# sdmmc_secure register map
Vendor: Texas Instruments
Peripheral module from a debugger description file (folder CC35X1E).
Registers are 32-bit, access per field, reset 0x0 unless marked. A register's access mark holds for its fields unless they carry their own. Offsets are as the file gives them; lines under a group give offsets from that group; [hi:lo] are bit positions; {n}, {i} and the like mark numbered series; 'fields as' and 'values as' point back to an identical list; <NAME> marks a mode.

## sdmmc_secure (part 1 of 2)
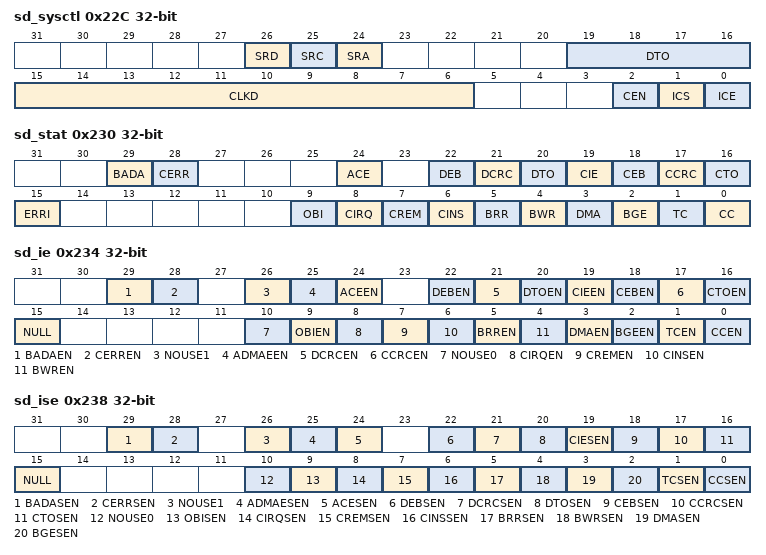
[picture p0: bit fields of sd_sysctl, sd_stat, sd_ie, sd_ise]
0x22C sd_sysctl — SD System Control Register This register defines the system controls clock frequency management and data timeout. SD_SYSCTL[23:16] = Timeout control SD_SYSCTL[15:0] = Clock control
  [26] SRD rw — Software reset for mmc_dat line This bit is set to 1 for reset and released to 0 when completed. Note: This subreset should not to be used by software, as it can lead to unexpected side-effects. Reset of the SDMMC module should always be through GPRCM.RSTCTL.RESETASSERT
    0=COMPL (Reset completed); 1=ASSERT (Reset asserted)
  [25] SRC rw — Software reset for mmc_cmd line This bit is set to 1 for reset and released to 0 when completed. Note: This subreset should not to be used by software, as it can lead to unexpected side-effects. Reset of the SDMMC module should always be through GPRCM.RSTCTL.RESETASSERT
    0=COMPL (Reset completed); 1=ASSERT (Reset asserted)
  [24] SRA rw — Software reset for all This bit is set to 1 for reset, and released to 0 when completed. Note: This subreset should not to be used by software, as it can lead to unexpected side-effects. Reset of the SDMMC module should always be through GPRCM.RSTCTL.RESETASSERT
    0=COMPL (Reset completed); 1=ASSERT (Reset asserted)
  [19:16] DTO rw — Data timeout counter value and busy timeout This value determines the interval to detect mmc_dat lines timeouts. The host driver needs to set this bitfield based on: - the maximum read access time (NAC) (Refer to the SD Specification Part1 Physical Layer) - the data read access time values (TAAC and NSAC) in the card specific data register (CSD) of the card - the timeout clock base frequency (SD_CAPA.TCF) If the card does not respond within the specified number of cycles, a data timeout error occurs (SD_STAT.DTO). The Data timeout counter can also be used to check busy duration, to generate busy timeout for commands with busy response or for busy programming during a write command. Timeout on CRC status is generated if no CRC token is present after a block write. 0h = TCF x 2^13 1h = TCF x 2^14 Eh = TCF x 2^27 Fh = Reserved
    0=MINIMUM (Minimum value); 14=MAXIMUM (Maximum value)
  [15:6] CLKD rw — Clock frequency select This bitfield defines the ratio between a reference clock frequency (system dependent) and the output clock frequency on the mmc_clk pin of the memory card (MMC, SD, or SDIO). 0h = Clock Ref bypass 1h = Clock Ref bypass 2h = Clock Ref / 2 3h = Clock Ref / 3 3FFh = Clock Ref / 1023
    0=MINIMUM (Minimum value); 0x3FF=MAXIMUM (Maximum value)
  [2] CEN rw — Card clock enable This bit controls the clock to the card.
    0=OFF (The clock is not provided to the card . Clock frequency can be changed.); 1=ON (The clock is provided to the card and can be automatically gated when SD_SYSCONFIG.AUTOIDLE bit is set to 1 (default value). The host driver must wait to set this bit to 1 until the internal clock is stable (SYSSTAT.ICS).)
  [1] ICS ro — Internal clock stable (status) This bit indicates that the internal clock is stable
    0=NOSTAB (The internal clock is not stable); 1=STAB (The internal clock is stable after enabling the clock (SD_SYSCTL.ICEN) or after changing the clock ratio (SD_SYSCTL.CLKD).)
  [0] ICE rw — Internal clock enable This bit controls the internal clock activity. In very low power state, the internal clock is stopped. Note: The activity of the debounce clock (used for wake-up events) and the interface clock (used for reads and writes to the module register map) are not affected by this register.
    0=STOP (The internal clock is stopped (very low power state).); 1=RUN (The internal clock oscillates and can be automatically gated when SD_SYSCONFIG.AUTOIDLE bit is set to 1 (default value).)
0x230 sd_stat — The interrupt status regroups all the status of the module internal events that can generate an interrupt. SD_STAT[31:16] = Error Interrupt Status SD_STAT[15:0] = Normal Interrupt Status The error bits are located in the upper 16 bits of the SD_STAT register. All bits are cleared by writing a 1 to them. Additionally, bits 15 and 8 serve as special error bits. These cannot be cleared by writing a 1 to them. Bit 15 (ERRI) is automatically cleared when the error causing to ERRI to be set is handled. (that is, when bits 31:16 are cleared, bit 15 will be automatically cleared). Bit 8 (CIRQ) is cleared by writing a 0 to SD_IE[8] (masking the interrupt) and servicing the interrupt.
  [all] fields
    0=NOINT (No interrupt occured); 1=INT (Interrupt occured)
  [29] BADA rw — Bad access to data space. This bit is set automatically to indicate a bad access to buffer when not allowed: During a read access to the data register (SD_DATA) while buffer reads are not allowed (SD_PSTATE[11] BRE bit =0). During a write access to the data register (SD_DATA) while buffer writes are not allowed (SD_PSTATE[10] BWE bit=0). 0h (W) = Status bit unchanged 0h (R) = No interrupt 1h (W) = Status is cleared. 1h (R) = Bad access
  [28] CERR rw — Card error. This bit is set automatically when there is at least one error in a response of type R1, R1b, R6, R5 or R5b. Only bits referenced as type E (error) in status field in the response can set a card status error. An error bit in the response is flagged only if corresponding bit in card status response error SD_CSRE in set. There is no card error detection for autoCMD12 command. The host driver shall read SD_RSP76 register to detect error bits in the command response. 0h (W) = Status bit unchanged 0h (R) = No error 1h (W) = Status is cleared. 1h (R) = Card error
  [24] ACE rw — Auto CMD12 error. This bit is set automatically when one of the bits in Auto CMD12 Error status register has changed from 0 to 1. 0h (W) = Status bit unchanged 0h (R) = No error 1h (W) = Status is cleared. 1h (R) = AutoCMD12 error
  [22] DEB rw — Data End Bit error. This bit is set automatically when detecting a 0 at the end bit position of read data on mmc_dat line or at the end position of the CRC status in write mode. 0h (W) = Status bit unchanged 0h (R) = No error 1h (W) = Status is cleared. 1h (R) = Data end bit error
  [21] DCRC rw — Data CRC Error. This bit is set automatically when there is a CRC16 error in the data phase response following a block read command or if there is a 3-bit CRC status different of a position "010" token during a block write command. 0h (W) = Status bit unchanged 0h (R) = No error 1h (W) = Status is cleared. 1h (R) = Data CRC error
  [20] DTO rw — Data timeout error. This bit is set automatically according to the following conditions: Busy timeout for R1b, R5b response type. Busy timeout after write CRC status. Write CRC status timeout. Read data timeout. 0h (W) = Status bit unchanged 0h (R) = No error 1h (W) = Status is cleared. 1h (R) = Time out
  [19] CIE rw — Command index error. This bit is set automatically when response index differs from corresponding command index previously emitted. It depends on the enable bit (SD_CMD[20] CICE). 0h (W) = Status bit unchanged 0h (R) = No error 1h (W) = Status is cleared. 1h (R) = Command index error
  [18] CEB rw — Command end bit error. This bit is set automatically when detecting a 0 at the end bit position of a command response. 0h (W) = Status bit unchanged 0h (R) = No error 1h (W) = Status is cleared. 1h (R) = Command end bit error
  [17] CCRC rw — Command CRC error. This bit is set automatically when there is a CRC7 error in the command response depending on the enable bit (SD_CMD[19] CCCE). 0h (W) = Status bit unchanged 0h (R) = No error 1h (W) = Status is cleared. 1h (R) = Command CRC error
  [16] CTO rw — Command timeout error. This bit is set automatically when no response is received within 64 clock cycles from the end bit of the command. For commands that reply within 5 clock cycles - the timeout is still detected at 64 clock cycles. 0h (W) = Status bit unchanged 0h (R) = No error 1h (W) = Status is cleared. 1h (R) = Time Out
  [15] ERRI ro — Error interrupt. If any of the bits in the Error Interrupt Status register (SD_STAT [31:16]) are set, then this bit is set to 1. Therefore the host driver can efficiently test for an error by checking this bit first. Writes to this bit are ignored. 0h (R) = No interrupt 1h (R) = Error interrupt event(s) occurred
  [9] OBI rw — Out-of-band interrupt (This interrupt is only useful for MMC card). Note: Out-of-band interrupt (OBI) is not supported.
  [8] CIRQ ro — Card interrupt. This bit is only used for SD and SDIO cards. In 1-bit mode, interrupt source is asynchronous (can be a source of asynchronous wake-up). In 4-bit mode, interrupt source is sampled during the interrupt cycle. In CE-ATA mode, interrupt source is detected when the card drives mmc_cmd line to zero during one cycle after data transmission end. All modes above are fully exclusive. The controller interrupt must be clear by setting SD_IE[8] CIRQ_ENABLE to 0, then the host driver must start the interrupt service with card (clearing card interrupt status) to remove card interrupt source. Otherwise the Controller interrupt will be reasserted as soon as SD_IE[8] CIRQ_ENABLE is set to 1. Writes to this bit are ignored. 0h (R) = No card interrupt 1h (R) = Generate card interrupt
  [7] CREM rw — Card Removal. This bit is set automatically when SD_PSTATE[CINS] changes from 1 to 0. A clear of this bit doesn't affect Card inserted present state (SD_PSTATE[CINS]). 0h (W) = Status bit unchanged 0h (R) = Card State stable or debouncing 1h (W) = Status is cleared 1h (R) = Card Removed
  [6] CINS rw — Card Insertion. This bit is set automatically when SD_PSTATE[CINS] changes from 0 to 1. A clear of this bit doesn't affect Card inserted present state (SD_PSTATE[CINS]). 0h (W) = Status bit unchanged 0h (R) = Card State stable or debouncing 1h (W) = Status is cleared. 1h (R) = Card inserted
  [5] BRR rw — Buffer read ready. This bit is set automatically during a read operation to the card (see class 2 - block oriented read commands) when one block specified by the SD_BLK [10:0] BLEN bit field is completely written in the buffer. It indicates that the memory card has filled out the buffer and that the local host needs to empty the buffer by reading it. Note: If the DMA receive-mode is enabled, this bit is never set instead a DMA receive request to the main DMA controller of the system is generated. 0h (W) = Status bit unchanged 0h (R) = Not ready to read buffer 1h (W) = Status is cleared. 1h (R) = Ready to read buffer
  [4] BWR rw — Buffer write ready. This bit is set automatically during a write operation to the card (see class 4 - block oriented write command) when the host can write a complete block as specified by SD_BLK [10:0] BLEN. It indicates that the memory card has emptied one block from the buffer and that the local host is able to write one block of data into the buffer. Note: If the DMA transmit mode is enabled, this bit is never set instead, a DMA transmit request to the main DMA controller of the system is generated. 0h (W) = Status bit unchanged 0h (R) = Not ready to write buffer 1h (W) = Status is cleared. 1h (R) = Ready to write buffer
  [3] DMA rw — DMA Interrupt This status is set when an interrupt is required after the data transfer is complete.
  [2] BGE rw — Block gap event. When a stop at block gap is requested (SD_HCTL[16] SBGR bit), this bit is automatically set when transaction is stopped at the block gap during a read or write operation. 0h (W) = Status bit unchanged 0h (R) = No block gap event 1h (W) = Status is cleared 1h (R) = Transaction stopped at block gap
  [1] TC rw — Transfer completed. This bit is always set when a read/write transfer is completed or between two blocks when the transfer is stopped due to a stop at block gap request (SD_HCTL[16] SBGR bit). 0h (W) = Status bit unchanged 0h (R) = No transfer complete 1h (W) = Status is cleared 1h (R) = Data transfer complete
  [0] CC rw — Command complete. This bit is set when a 1-to-0 transition occurs in the register command inhibit (SD_PSTATE[0] CMDI bit) 0h (W) = Status bit unchanged 0h (R) = No command complete 1h (W) = Status is cleared 1h (R) = Command complete
0x234 sd_ie — This register allows to enable/disable the module to set status bits on an event-by-event basis. SD_IE[31:16] = Error Interrupt Status Enable SD_IE[15:0] = Normal Interrupt Status Enable
  [29] BADAEN rw — Bad access to data space interrupt enable
    1=ENABLE (Interrupt enabled); 0=MSK (Interrupt masked)
  [28] CERREN rw — Card error interrupt enable
    1=ENABLE (Interrupt enabled); 0=MSK (Interrupt masked)
  [26] NOUSE1 rw — No use Note: Writing values other than 0 might produce undesired results. Always set this bits to 0.
    0=MIN (Minimum value); 1=MAX (Maximum value)
  [25] ADMAEEN rw — ADMA Error Status Enable Note: This functionality is not supported, since MADMA_EN is set to 0 in the design.
    1=ENABLE (Interrupt enabled); 0=MSK (Interrupt masked)
  [24] ACEEN rw — Auto CMD12 error interrupt enable
    1=ENABLE (Interrupt enabled); 0=MSK (Interrupt masked)
  [22] DEBEN rw — Data end bit error interrupt enable
    1=ENABLE (Interrupt enabled); 0=MSK (Interrupt masked)
  [21] DCRCEN rw — Data CRC error interrupt enable
    1=ENABLE (Interrupt enabled); 0=MSK (Interrupt masked)
  [20] DTOEN rw — Data timeout error interrupt enable
    1=ENABLE (Interrupt enabled); 0=MSK (Interrupt masked)
  [19] CIEEN rw — Command index error interrupt enable
    1=ENABLE (Interrupt enabled); 0=MSK (Interrupt masked)
  [18] CEBEN rw — Command end bit error interrupt enable
    1=ENABLE (Interrupt enabled); 0=MSK (Interrupt masked)
  [17] CCRCEN rw — Command CRC error interrupt enable
    1=ENABLE (Interrupt enabled); 0=MSK (Interrupt masked)
  [16] CTOEN rw — Command timeout error interrupt enable
    1=ENABLE (Interrupt enabled); 0=MSK (Interrupt masked)
  [15] NULL ro — Fixed to 0. The host driver shall control error interrupts using the Error Interrupt Signal Enable register. Writes to this bit are ignored.
    1=ENABLE (Interrupt enabled); 0=MSK (Interrupt masked)
  [10] NOUSE0 rw — No use Note: Writing values other than 0 might produce undesired results. Always set this bits to 0.
    0=MIN (Minimum value); 1=MAX (Maximum value)
  [9] OBIEN rw — Out-of-band interrupt enable A write to this register when SD_CON[14] OBIE is cleared to 0 is ignored. Note: The OBI functionallity is not supported!
    1=ENABLE (Interrupt enabled); 0=MSK (Interrupt masked)
  [8] CIRQEN rw — Card interrupt enable. A clear of this bit also clears the corresponding status bit. During 1-bit mode, if the interrupt routine does not remove the source of a card interrupt in the SDIO card, the status bit is reasserted when this bit is set to 1.
    1=ENABLE (Interrupt enabled); 0=MSK (Interrupt masked)
  [7] CREMEN rw — Card Removal interrupt Enable
    1=ENABLE (Interrupt enabled); 0=MSK (Interrupt masked)
  [6] CINSEN rw — Card Insertion interrupt Enable
    1=ENABLE (Interrupt enabled); 0=MSK (Interrupt masked)
  [5] BRREN rw — Buffer read ready interrupt enable
    1=ENABLE (Interrupt enabled); 0=MSK (Interrupt masked)
  [4] BWREN rw — Buffer write ready interrupt enable
    1=ENABLE (Interrupt enabled); 0=MSK (Interrupt masked)
  [3] DMAEN rw — DMA interrupt enable
    1=ENABLE (Interrupt enabled); 0=MSK (Interrupt masked)
  [2] BGEEN rw — Block gap event interrupt enable
    1=ENABLE (Interrupt enabled); 0=MSK (Interrupt masked)
  [1] TCEN rw — Transfer completed interrupt enable
    1=ENABLE (Interrupt enabled); 0=MSK (Interrupt masked)
  [0] CCEN rw — Command completed interrupt enable
    0=MSK (Interrupt masked); 1=ENABLE (Interrupt enabled)
0x238 sd_ise — This register allows to enable/disable the module internal interrupt signaling on an event-by-event basis. SD_ISE[31:16] = Error Interrupt Signal Enable SD_ISE[15:0] = Normal Interrupt Signal Enable
  [29] BADASEN rw — Bad access to data space interrupt enable
    0=DISABLE (Status Interrupt signaling disabled); 1=ENABLE (Status Interrupt signaling enabled)
  [28] CERRSEN rw — Card error interrupt signal status enable
    values as BADASEN
  [26] NOUSE1 rw — No use Note: Writing values other than 0 might produce undesired results. Always set this bit to 0.
    0=LOW (Always set this bit to 0); 1=HIGH (Do not set this bit)
  [25] ADMAESEN rw — ADMA Error Signal Enable Note: This functionality is not supported, since MADMA_EN is set to 0 in the design.
    values as BADASEN
  [24] ACESEN rw — Auto CMD12 error signal status enable
    values as BADASEN
  [22] DEBSEN rw — Data end bit error signal status enable
    values as BADASEN
  [21] DCRCSEN rw — Data CRC error signal status enable
    values as BADASEN
  [20] DTOSEN rw — Data timeout error signal status enable
    values as BADASEN
  [19] CIESEN rw — Command index error signal status enable
    values as BADASEN
  [18] CEBSEN rw — Command end bit error signal status enable
    values as BADASEN
  [17] CCRCSEN rw — Command CRC error signal status enable
    values as BADASEN
  [16] CTOSEN rw — Command timeout error signal status enable
    1=ENABLE (Status Interrupt signaling enabled); 0=DISABLE (Status Interrupt signaling disabled)
  [15] NULL ro — Fixed to 0. The host driver shall control error interrupts using the Error Interrupt Signal Enable register. Writes to this bit are ignored.
    1=ENABLE (Interrupt enabled); 0=MSK (Interrupt masked)
  [10] NOUSE0 rw — No use Note: Writing values other than 0 might produce undesired results. Always set this bit to 0.
    values as NOUSE1
  [9] OBISEN rw — Out-of-band interrupt signal status enable. A write to this register when SD_CON[14] OBIE is cleared to 0 is ignored. Note: The OBI functionallity is not supported!
    values as BADASEN
  [8] CIRQSEN rw — Card interrupt signal status enable. A clear of this bit also clears the corresponding status bit. During 1-bit mode, if the interrupt routine does not remove the source of a card interrupt in the SDIO card, the status bit is reasserted when this bit is set to 1.
    values as CTOSEN
  [7] CREMSEN rw — Card Removal signal status enable
    values as BADASEN
  [6] CINSSEN rw — Card Insertion signal status enable.
    values as BADASEN
  [5] BRRSEN rw — Buffer read ready signal status enable
    values as BADASEN
  [4] BWRSEN rw — Buffer write ready signal status enable
    values as BADASEN
  [3] DMASEN rw — DMA signal status enable
    values as BADASEN
  [2] BGESEN rw — Block gap event signal status enable
    values as BADASEN
  [1] TCSEN rw — Transfer completed signal status enable
    values as BADASEN
  [0] CCSEN rw — Command completed signal status enable
    values as BADASEN
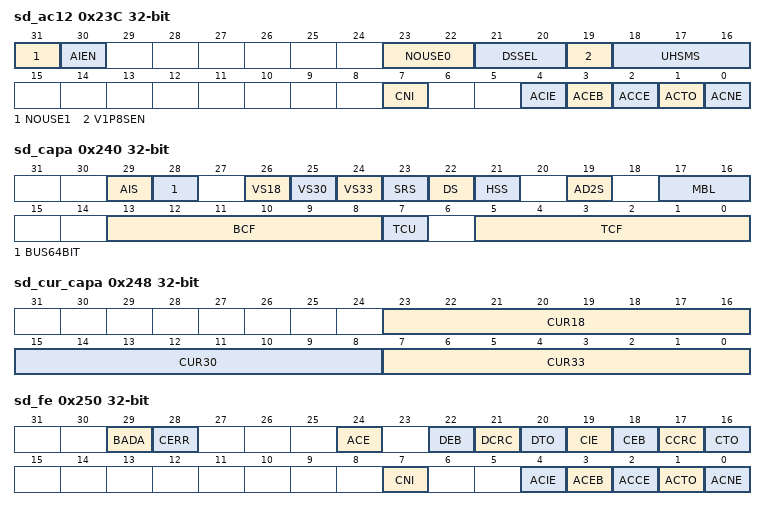
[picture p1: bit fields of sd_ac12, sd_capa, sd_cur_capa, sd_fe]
0x23C sd_ac12 — SD_AC12 Error register The host driver may determine which of the errors cases related to Auto CMD12 has occurred by checking this SD_AC12 register when an auto CMD12 error interrupt occurs. This register is valid only when auto CMD12 is enabled (SD_CMD.ACEN) and auto CMD12Error (SD_STAT.ACE) is set to 1. These bits are automatically reset when starting a new adtc command with data.
  [31] NOUSE1 rw — No use Note: Writing values other than 0 might produce undesired results. Always set this bit to 0.
    values as sd_ise.NOUSE1
  [30] AIEN rw — Asynchronous Interrupt Enable This bit can be set to 1 if a card supports asynchronous interrupts and Asynchronous Interrupt Support is set to 1 in the Capabilities register. Asynchronous interrupt is effective when DAT[1] interrupt is used in 4-bit SD mode (and zero is set to Interrupt Pin Select in the Shared Bus Control register). If this bit is set to 1, the Host Driver can stop the SDCLK during asynchronous interrupt period to save power. During this period, the Host Controller continues to deliver the Card Interrupt to the host when it is asserted by the Card.
    0=DISABLE (Asynchronous Interrupt disabled); 1=ENABLE (Asynchronous Interrupt enabled)
  [23:22] NOUSE0 rw — No use Note: Writing values other than 0 might produce undesired results. Always set this bit to 0.
    values as sd_ise.NOUSE1
  [21:20] DSSEL rw — Driver Strength Select Host Controller output driver in 1.8V signaling is selected by this bit. In 3.3V signaling, this field is not effective. This field can be set depends on Driver Type A, C and D support bits in the Capabilities register.
    0=TYPE_B (Driver Type B is selected); 1=TYPE_A (Driver Type A is selected); 2=TYPE_C (Driver Type C is selected); 3=TYPE_D (Driver Type D is selected)
  [19] V1P8SEN rw — 1.8V Signaling Enable This bit controls voltage regulator for I/O cell. 3.3V is supplied to the card regardless of signaling voltage. Setting this bit from 0 to 1 starts changing signal voltage from 3.3V to 1.8V. 1.8V regulator output shall be stable within 5ms. Host Controller clears this bit if switching to 1.8V signaling fails. Clearing this bit from 1 to 0 starts changing signal voltage from 1.8V to 3.3V. 3.3V regulator output shall be stable within 5ms. Host Driver can set this bit to 1 when Host Controller supports 1.8V signaling (One of support bits is set to 1: SDR50, SDR104 or DDR50 in the Capabilities register) and the card or device supports UHS-I (S18A=1. Refer to Bus Signal Voltage Switch Sequence in the Physical Layer Specification Version 3.0x). Note: Dragon supports only 3.3V. Always set this bit to 0.
    0=DISABLE (3.3V Signaling); 1=ENABLE (1.8V Signaling)
  [18:16] UHSMS rw — UHS Mode Select This field is used to select one of UHS-I modes or e.MMC HS200 mode and effective when 1.8V Signaling Enable is set to 1. Note: Dragon does not support 1.8V signaling and UHS modes. Always set this bitfield to 0.
    0=SDR12; 1=SDR25; 2=SDR50; 3=SDR104 (SDR104 / HS200); 4=DDR50
  [7] CNI ro — Command not issue by auto CMD12 error If this bit is set to 1, a pending command is not executed due to auto CMD12 error ACEB, ACCE, ACTO, or ACNE.
    0=NOERR (No error); 1=ERR (Error occurred)
  [4] ACIE ro — Auto CMD12 index error This bit is a set to 1 when response index differs from corresponding command auto CMD12 index previously emitted. This bit depends on the command index check enable (SD_CMD.CICEN).
    0=NOERR (No error); 1=ERR (Error occurred)
  [3] ACEB ro — Auto CMD12 end bit error. This bit is set to 1 when detecting a 0 at the end bit position of auto CMD12 command response.
    0=NOERR (No error); 1=ERR (Error occurred)
  [2] ACCE ro — Auto CMD12 CRC error. This bit is set to 1 when a CRC7 error is detected in the auto CMD12 command response.
    0=NOERR (No error); 1=ERR (Error occurred)
  [1] ACTO ro — Auto CMD12 timeout error. This bit is set to 1 if no response is received within 64 clock cycles from the end bit of the auto CMD12 command.
    0=NOERR (No error); 1=ERR (Error occurred)
  [0] ACNE ro — Auto CMD12 not executed. This bit is set to 1 if multiple block data transfer command has started and if an error occurs in command before auto CMD12 starts.
    0=NOERR (Auto CMD12 executed); 1=ERR (Auto CMD12 not executed)
0x240 sd_capa reset not defined — Capability register This register lists the capabilities of the MMC/SD/SDIO host controller.
  [29] AIS ro — Asynchronous Interrupt Support Refer to SDIO Specification Version 3.00 about asynchronous interrupt.
    0=NOSUPPORT (Not supported); 1=SUPPORT (Supported)
  [28] BUS64BIT ro — 64 Bit System Bus Support Setting 1 to this bit indicates that the Host Controller supports 64-bit address descriptor mode and is connected to 64-bit address system bus. 0h (R) = 32-bit System bus address 1h (R) = 64-bit System bus address
    0=NOSUPPORT (Not supported); 1=SUPPORT (Supported)
  [26] VS18 rw — Voltage support 1.8 V Initialization of this register (via a write access to this register) depends on the system capabilities. The host driver shall not modify this register after the initialization. This register is only reinitialized by a hard reset (via mmc_RESET signal). 0h (W) = 1.8 V not supported 0h (R) = 1.8 V not supported 1h (W) = 1.8 V supported 1h (R) = 1.8 V supported
    0=NOSUPPORT (Not supported); 1=SUPPORT (Supported)
  [25] VS30 rw — Voltage support 3.0V Initialization of this register (via a write access to this register) depends on the system capabilities. The host driver shall not modify this register after the initialization. This register is only reinitialized by a hard reset (via mmc_RESET signal). 0h (W) = 3.0 V not supported 0h (R) = 3.0 V not supported 1h (W) = 3.0 V supported 1h (R) = 3.0 V supported
    0=NOSUPPORT (Not supported); 1=SUPPORT (Supported)
  [24] VS33 rw — Voltage support 3.3V Initialization of this register (via a write access to this register) depends on the system capabilities. The host driver shall not modify this register after the initialization. This register is only reinitialized by a hard reset (via mmc_RESET signal). 0h (W) = 3.3 V not supported 0h (R) = 3.3 V not supported 1h (W) = 3.3 V supported 1h (R) = 3.3 V supported
    0=NOSUPPORT (Not supported); 1=SUPPORT (Supported)
  [23] SRS ro — Suspend/resume support (SDIO cards only). This bit indicates whether the host controller supports suspend/resume functionality.
    0=NOSUPPORT (Not supported); 1=SUPPORT (Supported)
  [22] DS ro — DMA support This bit indicates that the Host controller is able to use DMA to transfer data between system memory and the Host controller directly.
    0=NOSUPPORT (Not supported); 1=SUPPORT (Supported)
  [21] HSS ro — High-speed support This bit indicates that the host controller supports high speed operations and can supply an up-to-52 MHz clock to the card.
    0=NOSUPPORT (Not supported); 1=SUPPORT (Supported)
  [19] AD2S ro — This bit indicates whether the Host Controller is capable of using ADMA2.
    1=SUPPORT (Supported); 0=NOSUPPORT (Not supported)
  [17:16] MBL ro — Maximum block length This value indicates the maximum block size that the host driver can read and write to the buffer in the host controller. The host controller supports 512 bytes and 1024 bytes block transfers. 0h = 512 bytes 1h = 1024 bytes 2h = 2048 bytes
    0=MINIMUM (Minimum value); 3=MAXIMUM (Maximum value)
  [13:8] BCF ro — Base clock frequency for clock provided to the card. ARRAY(0x1bfe1b0)
    0=MINIMUM (Minimum value); 63=MAXIMUM (Maximum value)
  [7] TCU ro — Timeout clock unit This bit shows the unit of base clock frequency used to detect Data Timeout Error.
    0=KHZ; 1=MHZ
  [5:0] TCF ro — Timeout clock frequency The timeout clock frequency is used to detect Data Timeout Error (DTO interrupt). The timeout clock frequency depends on the frequency of the clock provided to the card. The value of the timeout clock frequency is not available in this register.
    0=MINIMUM (Minimum value); 63=MAXIMUM (Maximum value)
0x248 sd_cur_capa — Current capability register This register indicates the maximum current capability for each voltage.
  [all] fields
    0=MINIMUM (Minimum value); 255=MAXIMUM (Maximum value)
  [23:16] CUR18 rw — Maximum current for 1.8V The maximum current capability for this voltage is not available. Feature not implemented.
  [15:8] CUR30 rw — Maximum current for 3.0V The maximum current capability for this voltage is not available. Feature not implemented.
  [7:0] CUR33 rw — Maximum current for 3.3V The maximum current capability for this voltage is not available. Feature not implemented.
0x250 sd_fe — The Force Event register is not a physically implemented register. Rather, it is an address at which the Error Interrupt Status register can be written. The effect of a write to this address will be reflected in the Error Interrupt Status Register, if corresponding bit of the Error Interrupt Status Enable Register is set.
  [all] fields
    0=NOINT (No interrupt); 1=INT (Interrupt forced)
  [29] BADA wo — Force Event Bad access to data space
  [28] CERR wo — Force Event Card error
  [24] ACE wo — Force Event Auto CMD12 error
  [22] DEB wo — Force Event Data End Bit error
  [21] DCRC wo — Force Event Data CRC error
  [20] DTO wo — Force Event Data timeout error
  [19] CIE wo — Force Event Command index error
  [18] CEB wo — Force Event Command end bit error
  [17] CCRC wo — Force Event Comemand CRC error
  [16] CTO wo — Force Event Command Timeout error
  [7] CNI wo — Force Event Command not issue by Auto CMD12 error
  [4] ACIE wo — Force Event Auto CMD12 index error
  [3] ACEB wo — Force Event Auto CMD12 end bit error
  [2] ACCE wo — Force Event Auto CMD12 CRC error
  [1] ACTO wo — Force Event Auto CMD12 timeout error
  [0] ACNE wo — Force Event Auto CMD12 not executed.
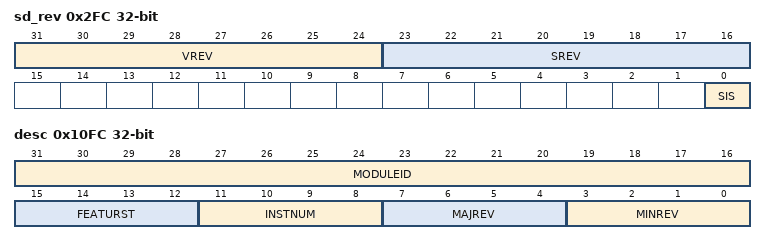
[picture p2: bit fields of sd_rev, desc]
0x2FC sd_rev ro reset not defined — Revision register This register contains the hard coded RTL vendor revision number, the version number of SD specification compliancy.
  [31:24] VREV — Vendor Version Number Bits 7 to 4 are the major revision, bits 3 to 0 are the minor revision. Examples: 0x10 for 1.0 and 0x21 for 2.1. Reset value is 0x31.
    0=MINIMUM (Minimum value); 255=MAXIMUM (Maximum value)
  [23:16] SREV — Specification Version Number This status indicates the Standard SD Host Controller Specification Version. The upper and lower 4 bits indicate the version. 0h: SD Host Specification Version 1.00. 1h: SD Host Specification Version 2.00. 2h: SD Host Specification Version 3.00. 3h: Reserved
    0=MINIMUM (Minimum value); 255=MAXIMUM (Maximum value)
  [0] SIS — Slot Interrupt Status This status bit indicates the inverted state of interrupt signal for the module. By a power on reset or by setting a software reset for all, the interrupt signal shall be deasserted and this status shall read 0.
    0=NOINT (No interrupt is asserted); 1=INT (Interrupt is asserted)
0x1040 tp_select — Test-Port select.
  [0] VAL rw — Test port 0 or 1
    0=TEST_PORT1; 1=TEST_PORT2
0x1048 dma_mode_select reset 0x3 — DMA mode select: This register define the behavior of DMA request signal that allow tranmission of data.
  [0] VAL rw — 0h = In this case, DMA required to read/write data from SD_DATA register, the value of DMA_INDICATION_SELECT register is d'ont care and the trigger to transmit data from the internal FIFO defined by SD_BLK.BLEN register as a threshold. 1h = DMA required to read/write data from BUFIF register the value of DMA_INDICATION_SELECT define the trigger of the internal FIFO.
    0=DISABLE (Disable to trig the internal FIFO with threshold, using DMA indication instead); 1=ENABLE (Enable to trig the internal FIFO with threshold)
0x1050 dma_indication_select reset 0x3 — DMA indication select: This register define the behavior of transmitting data from/to the card using DMA If DMA_MODE_SELECT =1, then the value of of this register is d'ont care, else it define the trigger of the internal FIFO
  [0] VAL rw — 0h = IP transmit the data to/from the card after each DMA 'BLOCK' transmitted. In this case SDMMC.SD_BLK.BLEN shoud be equal to HOST_DMA.JOB_CTRL_CH7.MEM_JOB_CTRL_CHAN_7_BLOCK_SIZE 1h = IP transmit the data to the card after each DMA 'JOB' transmitted. In this case SDMMC.SD_BLK.BLEN shoud be equal to HOST_DMA.TRANS_CTRL_CH7.MEM_TRANS_CTRL_CHAN_7_TRANS_NUM_B
    0=DMA_BLK (The IP transmit the data to/from the card, after each DMA transmitted block.); 1=DMA_JOB (The IP transmit the data to/from the card, only in the end of the DMA job.)
0x1054 mem_clk_sel — This register define the functional clock frequency, and whether the clock is synchronized to main clock.
  [0] VAL rw — 0h = 40MHz post-swallowing 1h = 80MHz pro-swallowing
    0=SYNC (post-swallowing 40MHz clock to main clock); 1=ASYNC (pre-swallowing 80MHz clock)
0x10E0 evt_mode reset 0x5 — Event mode register. It is used to select whether each line is disabled, in software mode (software clears the RIS) or in hardware mode (hardware clears the RIS)
  [1:0] INT0CFG rw — Event line mode select for event corresponding to [IPSTANDARD.INT_EVENT0]
    0=DISABLE (The interrupt or event line is disabled.); 1=SOFTWARE (The interrupt or event line is in software mode. Software must clear the RIS.); 2=HARDWARE (The interrupt or event line is in hardware mode. The hardware (another module) clears automatically the associated RIS flag.)
0x10FC desc ro reset not defined — This register identifies the peripheral and its exact version.
  [31:16] MODULEID — Module identification contains a unique peripheral identification number. The assignments are maintained in a central database for all of the platform modules to ensure uniqueness.
    0=MINIMUM (Smallest value); 0xFFFF=MAXIMUM (Highest possible value)
  [15:12] FEATURST — Feature Set for the module *instance*
    0=MINIMUM (Smallest value); 15=MAXIMUM (Highest possible value)
  [11:8] INSTNUM — Instance Number within the device. This will be a parameter to the RTL for modules that can have multiple instances
    values as FEATURST
  [7:4] MAJREV — Major rev of the IP
    values as FEATURST
  [3:0] MINREV — Minor rev of the IP
    values as FEATURST
0x1100 sdmmcstat ro — SDMMC Status register
  [0] STATE — SDMMC state indication
    0=NORMAL (IP is active but is not transmitting); 1=ACTIVE (IP is active and transmitting)
0x1110 bufif rw — SRAM Data Access Registers These registers are the 32-bit entry point of the SRAM buffer for read or write data transfers to and from the SDMMC card. Data[1] register is an alias for the SD_BUFIF register and needs to be used for normal (non safety, non burst) buffer accesses. Data[1..4] registers need to be used for non safety, incremental VBUSP burst accesses. For safety accesses (write with readback and double read), DataS[1..4] registers need to be used. The SRAM buffer size is 32bits x 256 (1024 bytes). Bytes within a word are stored and read in little endian format. This buffer can be used as two 512 byte buffers to transfer data efficiently without reducing the throughput. Sequential and contiguous access is necessary to increment the pointer correctly. Random or skipped access is not allowed. If the local host accesses this register byte-wise or 16bit-wise, the least significant byte (bits [7:0]) must always be written/read first. The update of the buffer address is done on the most significant byte write.
  [31:0] DATA — Buffer data register In functional mode (SD_CON.MODE = FUNC): - a read access to this register is allowed only when the buffer read enable status is set to 1 (SD_PSTATE.BREN), otherwise a bad access (SD_STAT.BADA) is signaled. - a write access to this register is allowed only when the buffer write enable status is set to 1 (SD_PSTATE.BWEN), otherwise a bad access (SD_STAT.BADA) is signaled and the data is not written.
    0=MINIMUM (Minimum value); 0xFFFFFFFF=MAXIMUM (Maximum value)
0x4000 clk_en_reg — Clock Enable Register
  [0] EN rw — Clock Disable / Enable for: * bus_clk (main clock) - 80MHz ; * card_clk (pll_clk) - 40MHz ; * lf_clk (slow_clk) - 32KHz ;
